# NAVSS0_NORTH_1_NBSS_NB1_CFG_MMRS register map
Vendor: Texas Instruments
Peripheral module from a debugger description file (folder J721S2).
Registers are 32-bit, read-only, reset 0x66100101 unless marked. A register's access mark holds for its fields unless they carry their own. Offsets are as the file gives them; lines under a group give offsets from that group; [hi:lo] are bit positions; {n}, {i} and the like mark numbered series; 'fields as' and 'values as' point back to an identical list; <NAME> marks a mode.

## NAVSS0_NORTH_1_NBSS_NB1_CFG_MMRS
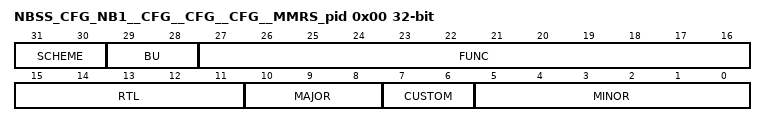
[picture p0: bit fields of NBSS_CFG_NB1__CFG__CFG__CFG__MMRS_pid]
0x00 NBSS_CFG_NB1__CFG__CFG__CFG__MMRS_pid — The Revision Register contains the major and minor revisions for the module.
  [31:30] SCHEME — PID register scheme
  [29:28] BU — Business Unit: 10 = Processors
  [27:16] FUNC — Module ID
  [15:11] RTL — RTL revision. Will vary depending on release.
  [10:8] MAJOR — Major revision
  [7:6] CUSTOM
  [5:0] MINOR — Minor revision
0x10 NBSS_CFG_NB1__CFG__CFG__CFG__MMRS_threadmap rw reset 0x0 — The Thread Map Register defines the vbusmc thread for each vbusm source.
  [2:0] THREADMAP — Thread map, each bit is for each vbusm source. A bit of 0 maps to vbusmc thread 0, a bit of 1 maps to vbusmc thread 2.
